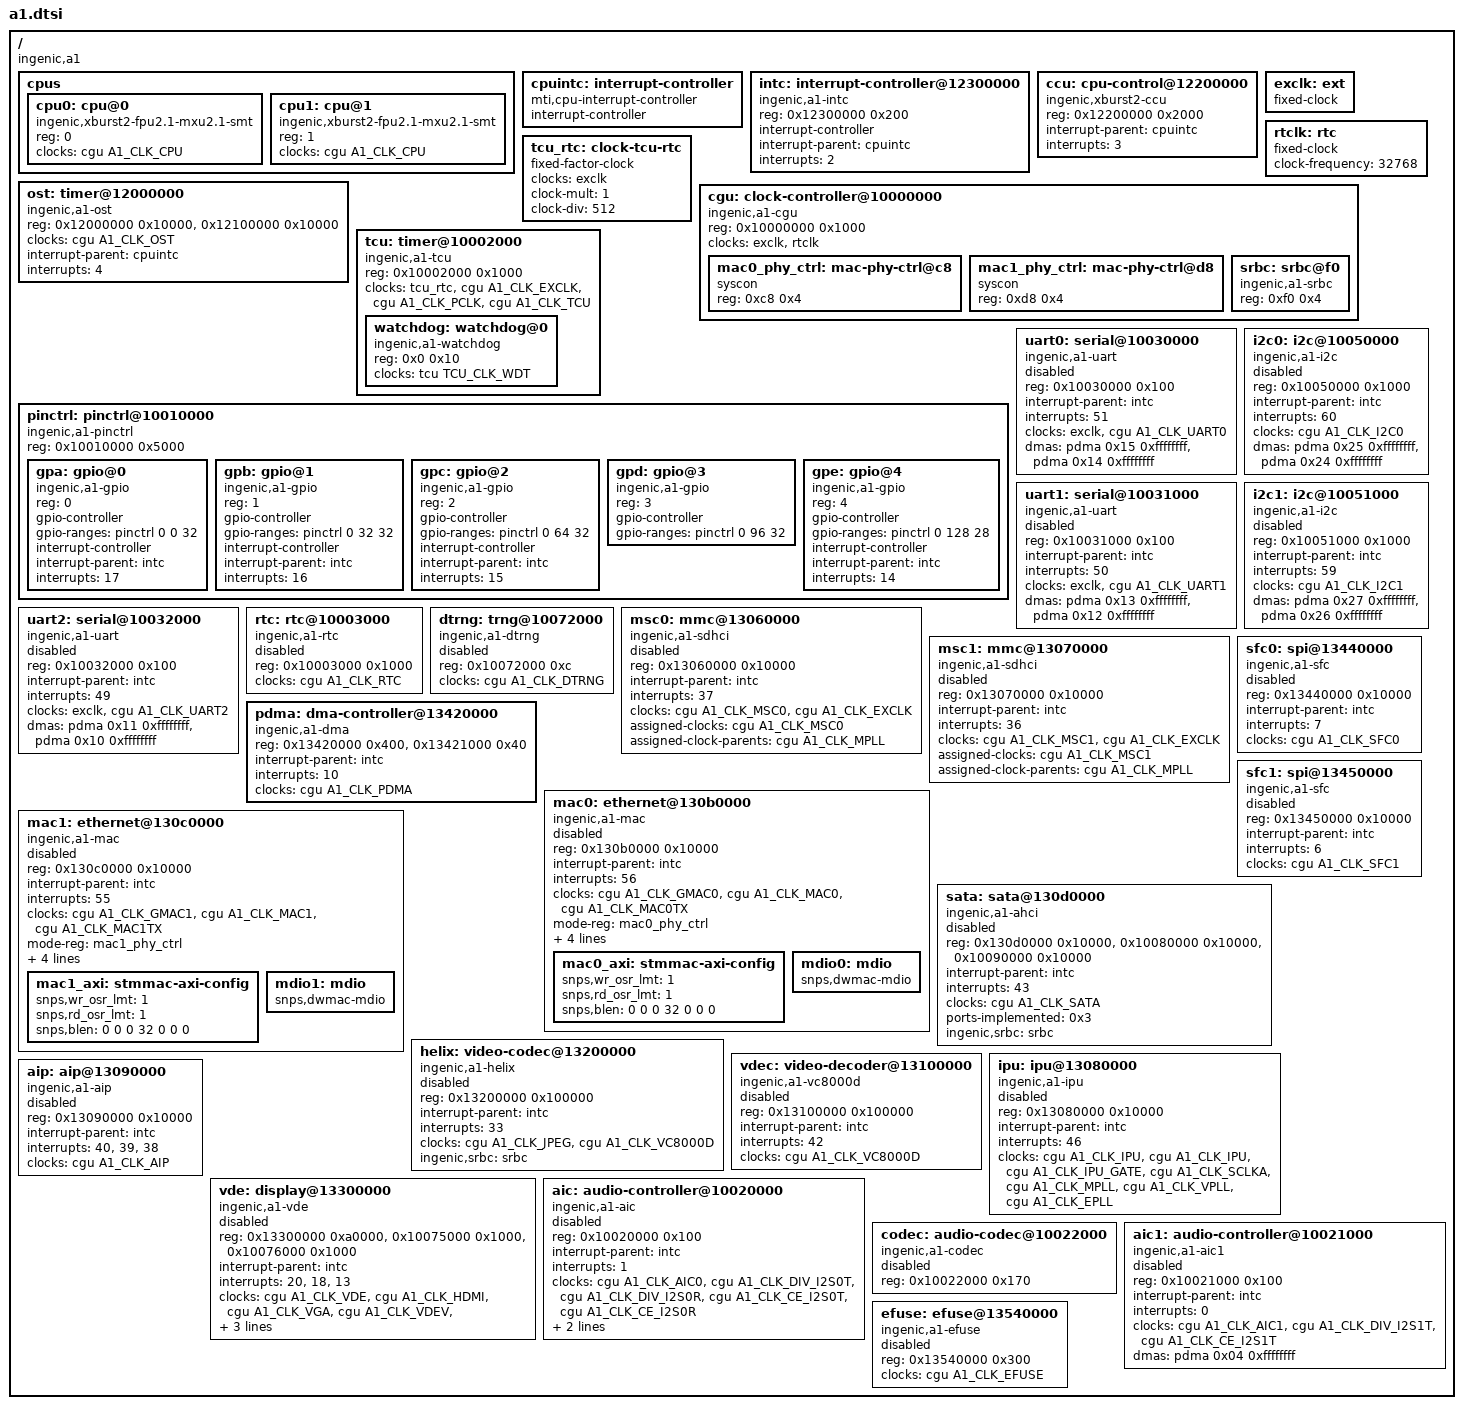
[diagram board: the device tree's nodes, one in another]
// SPDX-License-Identifier: GPL-2.0
#include <dt-bindings/clock/ingenic,a1-cgu.h>
#include <dt-bindings/clock/ingenic,tcu.h>

/ {
	#address-cells = <1>;
	#size-cells = <1>;
	compatible = "ingenic,a1";

	cpus {
		#address-cells = <1>;
		#size-cells = <0>;

		cpu0: cpu@0 {
			device_type = "cpu";
			compatible = "ingenic,xburst2-fpu2.1-mxu2.1-smt";
			reg = <0>;

			clocks = <&cgu A1_CLK_CPU>;
		};

		cpu1: cpu@1 {
			device_type = "cpu";
			compatible = "ingenic,xburst2-fpu2.1-mxu2.1-smt";
			reg = <1>;

			clocks = <&cgu A1_CLK_CPU>;
		};
	};

	cpuintc: interrupt-controller {
		#address-cells = <0>;
		#interrupt-cells = <1>;
		interrupt-controller;
		compatible = "mti,cpu-interrupt-controller";
	};

	/* One 0x100 window per core */
	intc: interrupt-controller@12300000 {
		compatible = "ingenic,a1-intc", "ingenic,t41-intc";
		reg = <0x12300000 0x200>;

		interrupt-controller;
		#interrupt-cells = <1>;

		interrupt-parent = <&cpuintc>;
		interrupts = <2>;
	};

	ccu: cpu-control@12200000 {
		compatible = "ingenic,xburst2-ccu";
		reg = <0x12200000 0x2000>;

		interrupt-parent = <&cpuintc>;
		interrupts = <3>;
	};

	exclk: ext {
		compatible = "fixed-clock";
		#clock-cells = <0>;
	};

	rtclk: rtc {
		compatible = "fixed-clock";
		#clock-cells = <0>;
		clock-frequency = <32768>;
	};

	/* RTC_EN of the TCU clocks EXCLK / 512, not the 32 kHz */
	tcu_rtc: clock-tcu-rtc {
		compatible = "fixed-factor-clock";
		clocks = <&exclk>;
		clock-mult = <1>;
		clock-div = <512>;
		#clock-cells = <0>;
	};

	cgu: clock-controller@10000000 {
		compatible = "ingenic,a1-cgu", "simple-mfd";
		reg = <0x10000000 0x1000>;
		#address-cells = <1>;
		#size-cells = <1>;
		ranges = <0x0 0x10000000 0x1000>;

		#clock-cells = <1>;

		clocks = <&exclk>, <&rtclk>;
		clock-names = "ext", "rtc";

		mac0_phy_ctrl: mac-phy-ctrl@c8 {
			compatible = "syscon";
			reg = <0xc8 0x4>;
		};

		mac1_phy_ctrl: mac-phy-ctrl@d8 {
			compatible = "syscon";
			reg = <0xd8 0x4>;
		};

		srbc: srbc@f0 {
			compatible = "ingenic,a1-srbc", "syscon";
			reg = <0xf0 0x4>;
		};
	};

	ost: timer@12000000 {
		compatible = "ingenic,a1-ost", "ingenic,t41-ost";
		reg = <0x12000000 0x10000>, <0x12100000 0x10000>;
		reg-names = "global", "core";

		clocks = <&cgu A1_CLK_OST>;
		clock-names = "ost";

		interrupt-parent = <&cpuintc>;
		interrupts = <4>;
	};

	tcu: timer@10002000 {
		compatible = "ingenic,a1-tcu", "ingenic,t32-tcu", "simple-mfd";
		reg = <0x10002000 0x1000>;
		#address-cells = <1>;
		#size-cells = <1>;
		ranges = <0x0 0x10002000 0x1000>;

		#clock-cells = <1>;

		clocks = <&tcu_rtc>,
			 <&cgu A1_CLK_EXCLK>,
			 <&cgu A1_CLK_PCLK>,
			 <&cgu A1_CLK_TCU>;
		clock-names = "rtc", "ext", "pclk", "tcu";

		watchdog: watchdog@0 {
			compatible = "ingenic,a1-watchdog", "ingenic,jz4780-watchdog";
			reg = <0x0 0x10>;

			clocks = <&tcu TCU_CLK_WDT>;
			clock-names = "wdt";
		};
	};

	pinctrl: pinctrl@10010000 {
		compatible = "ingenic,a1-pinctrl";
		reg = <0x10010000 0x5000>;

		#address-cells = <1>;
		#size-cells = <0>;

		gpa: gpio@0 {
			compatible = "ingenic,a1-gpio";
			reg = <0>;

			gpio-controller;
			gpio-ranges = <&pinctrl 0 0 32>;
			#gpio-cells = <2>;

			interrupt-controller;
			#interrupt-cells = <2>;

			interrupt-parent = <&intc>;
			interrupts = <17>;
		};

		gpb: gpio@1 {
			compatible = "ingenic,a1-gpio";
			reg = <1>;

			gpio-controller;
			gpio-ranges = <&pinctrl 0 32 32>;
			#gpio-cells = <2>;

			interrupt-controller;
			#interrupt-cells = <2>;

			interrupt-parent = <&intc>;
			interrupts = <16>;
		};

		gpc: gpio@2 {
			compatible = "ingenic,a1-gpio";
			reg = <2>;

			gpio-controller;
			gpio-ranges = <&pinctrl 0 64 32>;
			#gpio-cells = <2>;

			interrupt-controller;
			#interrupt-cells = <2>;

			interrupt-parent = <&intc>;
			interrupts = <15>;
		};

		/* No interrupt line */
		gpd: gpio@3 {
			compatible = "ingenic,a1-gpio";
			reg = <3>;

			gpio-controller;
			gpio-ranges = <&pinctrl 0 96 32>;
			#gpio-cells = <2>;
		};

		gpe: gpio@4 {
			compatible = "ingenic,a1-gpio";
			reg = <4>;

			gpio-controller;
			gpio-ranges = <&pinctrl 0 128 28>;
			#gpio-cells = <2>;

			interrupt-controller;
			#interrupt-cells = <2>;

			interrupt-parent = <&intc>;
			interrupts = <14>;
		};
	};

	uart0: serial@10030000 {
		compatible = "ingenic,a1-uart", "ingenic,x1000-uart";
		reg = <0x10030000 0x100>;

		interrupt-parent = <&intc>;
		interrupts = <51>;

		clocks = <&exclk>, <&cgu A1_CLK_UART0>;
		clock-names = "baud", "module";

		dmas = <&pdma 0x15 0xffffffff>, <&pdma 0x14 0xffffffff>;
		dma-names = "rx", "tx";

		status = "disabled";
	};

	uart1: serial@10031000 {
		compatible = "ingenic,a1-uart", "ingenic,x1000-uart";
		reg = <0x10031000 0x100>;

		interrupt-parent = <&intc>;
		interrupts = <50>;

		clocks = <&exclk>, <&cgu A1_CLK_UART1>;
		clock-names = "baud", "module";

		dmas = <&pdma 0x13 0xffffffff>, <&pdma 0x12 0xffffffff>;
		dma-names = "rx", "tx";

		status = "disabled";
	};

	uart2: serial@10032000 {
		compatible = "ingenic,a1-uart", "ingenic,x1000-uart";
		reg = <0x10032000 0x100>;

		interrupt-parent = <&intc>;
		interrupts = <49>;

		clocks = <&exclk>, <&cgu A1_CLK_UART2>;
		clock-names = "baud", "module";

		dmas = <&pdma 0x11 0xffffffff>, <&pdma 0x10 0xffffffff>;
		dma-names = "rx", "tx";

		status = "disabled";
	};

	i2c0: i2c@10050000 {
		compatible = "ingenic,a1-i2c", "ingenic,x1000-i2c";
		reg = <0x10050000 0x1000>;

		interrupt-parent = <&intc>;
		interrupts = <60>;

		clocks = <&cgu A1_CLK_I2C0>;

		dmas = <&pdma 0x25 0xffffffff>, <&pdma 0x24 0xffffffff>;
		dma-names = "rx", "tx";

		#address-cells = <1>;
		#size-cells = <0>;

		status = "disabled";
	};

	i2c1: i2c@10051000 {
		compatible = "ingenic,a1-i2c", "ingenic,x1000-i2c";
		reg = <0x10051000 0x1000>;

		interrupt-parent = <&intc>;
		interrupts = <59>;

		clocks = <&cgu A1_CLK_I2C1>;

		dmas = <&pdma 0x27 0xffffffff>, <&pdma 0x26 0xffffffff>;
		dma-names = "rx", "tx";

		#address-cells = <1>;
		#size-cells = <0>;

		status = "disabled";
	};

	rtc: rtc@10003000 {
		compatible = "ingenic,a1-rtc";
		reg = <0x10003000 0x1000>;

		clocks = <&cgu A1_CLK_RTC>;

		status = "disabled";
	};

	dtrng: trng@10072000 {
		compatible = "ingenic,a1-dtrng", "ingenic,x1830-dtrng";
		reg = <0x10072000 0xc>;

		clocks = <&cgu A1_CLK_DTRNG>;

		status = "disabled";
	};

	msc0: mmc@13060000 {
		compatible = "ingenic,a1-sdhci", "ingenic,t32-sdhci";
		reg = <0x13060000 0x10000>;

		interrupt-parent = <&intc>;
		interrupts = <37>;

		clocks = <&cgu A1_CLK_MSC0>, <&cgu A1_CLK_EXCLK>;
		clock-names = "mmc", "ext";

		/* the MSC mux may be left on a source the CGU does not list */
		assigned-clocks = <&cgu A1_CLK_MSC0>;
		assigned-clock-parents = <&cgu A1_CLK_MPLL>;

		status = "disabled";
	};

	msc1: mmc@13070000 {
		compatible = "ingenic,a1-sdhci", "ingenic,t32-sdhci";
		reg = <0x13070000 0x10000>;

		interrupt-parent = <&intc>;
		interrupts = <36>;

		clocks = <&cgu A1_CLK_MSC1>, <&cgu A1_CLK_EXCLK>;
		clock-names = "mmc", "ext";

		/* the MSC mux may be left on a source the CGU does not list */
		assigned-clocks = <&cgu A1_CLK_MSC1>;
		assigned-clock-parents = <&cgu A1_CLK_MPLL>;

		status = "disabled";
	};

	pdma: dma-controller@13420000 {
		compatible = "ingenic,a1-dma", "ingenic,x1830-dma";
		reg = <0x13420000 0x400>, <0x13421000 0x40>;

		interrupt-parent = <&intc>;
		interrupts = <10>;

		clocks = <&cgu A1_CLK_PDMA>;

		#dma-cells = <2>;
	};

	sfc0: spi@13440000 {
		compatible = "ingenic,a1-sfc", "ingenic,t32-sfc";
		reg = <0x13440000 0x10000>;

		interrupt-parent = <&intc>;
		interrupts = <7>;

		clocks = <&cgu A1_CLK_SFC0>;
		clock-names = "sfc";

		#address-cells = <1>;
		#size-cells = <0>;

		status = "disabled";
	};

	sfc1: spi@13450000 {
		compatible = "ingenic,a1-sfc", "ingenic,t32-sfc";
		reg = <0x13450000 0x10000>;

		interrupt-parent = <&intc>;
		interrupts = <6>;

		clocks = <&cgu A1_CLK_SFC1>;
		clock-names = "sfc";

		#address-cells = <1>;
		#size-cells = <0>;

		status = "disabled";
	};

	mac0: ethernet@130b0000 {
		compatible = "ingenic,a1-mac", "snps,dwxgmac-2.10", "snps,dwxgmac";
		reg = <0x130b0000 0x10000>;

		interrupt-parent = <&intc>;
		interrupts = <56>;
		interrupt-names = "macirq";

		clocks = <&cgu A1_CLK_GMAC0>, <&cgu A1_CLK_MAC0>,
			 <&cgu A1_CLK_MAC0TX>;
		clock-names = "stmmaceth", "phy", "tx";

		mode-reg = <&mac0_phy_ctrl>;

		snps,axi-config = <&mac0_axi>;
		snps,txpbl = <32>;
		snps,rxpbl = <32>;
		snps,force_sf_dma_mode;

		status = "disabled";

		mac0_axi: stmmac-axi-config {
			snps,wr_osr_lmt = <1>;
			snps,rd_osr_lmt = <1>;
			snps,blen = <0 0 0 32 0 0 0>;
		};

		mdio0: mdio {
			compatible = "snps,dwmac-mdio";
			#address-cells = <1>;
			#size-cells = <0>;
		};
	};

	mac1: ethernet@130c0000 {
		compatible = "ingenic,a1-mac", "snps,dwxgmac-2.10", "snps,dwxgmac";
		reg = <0x130c0000 0x10000>;

		interrupt-parent = <&intc>;
		interrupts = <55>;
		interrupt-names = "macirq";

		clocks = <&cgu A1_CLK_GMAC1>, <&cgu A1_CLK_MAC1>,
			 <&cgu A1_CLK_MAC1TX>;
		clock-names = "stmmaceth", "phy", "tx";

		mode-reg = <&mac1_phy_ctrl>;

		snps,axi-config = <&mac1_axi>;
		snps,txpbl = <32>;
		snps,rxpbl = <32>;
		snps,force_sf_dma_mode;

		status = "disabled";

		mac1_axi: stmmac-axi-config {
			snps,wr_osr_lmt = <1>;
			snps,rd_osr_lmt = <1>;
			snps,blen = <0 0 0 32 0 0 0>;
		};

		mdio1: mdio {
			compatible = "snps,dwmac-mdio";
			#address-cells = <1>;
			#size-cells = <0>;
		};
	};

	sata: sata@130d0000 {
		compatible = "ingenic,a1-ahci";
		reg = <0x130d0000 0x10000>, <0x10080000 0x10000>,
		      <0x10090000 0x10000>;
		reg-names = "ahci", "phy0", "phy1";

		interrupt-parent = <&intc>;
		interrupts = <43>;

		clocks = <&cgu A1_CLK_SATA>;

		ports-implemented = <0x3>;
		ingenic,srbc = <&srbc>;

		status = "disabled";
	};

	helix: video-codec@13200000 {
		compatible = "ingenic,a1-helix";
		reg = <0x13200000 0x100000>;

		interrupt-parent = <&intc>;
		interrupts = <33>;

		clocks = <&cgu A1_CLK_JPEG>, <&cgu A1_CLK_VC8000D>;
		clock-names = "gate_jpeg", "gate_vc8000d";

		ingenic,srbc = <&srbc>;

		status = "disabled";
	};

	vdec: video-decoder@13100000 {
		compatible = "ingenic,a1-vc8000d";
		reg = <0x13100000 0x100000>;

		interrupt-parent = <&intc>;
		interrupts = <42>;

		clocks = <&cgu A1_CLK_VC8000D>;
		clock-names = "gate_vc8000d";

		status = "disabled";
	};

	ipu: ipu@13080000 {
		compatible = "ingenic,a1-ipu";
		reg = <0x13080000 0x10000>;

		interrupt-parent = <&intc>;
		interrupts = <46>;

		/* the vendor stack names the mux and the divider apart; here they are one clock */
		clocks = <&cgu A1_CLK_IPU>, <&cgu A1_CLK_IPU>,
			 <&cgu A1_CLK_IPU_GATE>, <&cgu A1_CLK_SCLKA>,
			 <&cgu A1_CLK_MPLL>, <&cgu A1_CLK_VPLL>,
			 <&cgu A1_CLK_EPLL>;
		clock-names = "mux_ipu", "div_ipu", "gate_ipu", "sclka",
			      "mpll", "vpll", "epll";

		status = "disabled";
	};

	aip: aip@13090000 {
		compatible = "ingenic,a1-aip";
		reg = <0x13090000 0x10000>;

		interrupt-parent = <&intc>;
		interrupts = <40>, <39>, <38>;

		clocks = <&cgu A1_CLK_AIP>;
		clock-names = "gate_aip";

		status = "disabled";
	};

	vde: display@13300000 {
		compatible = "ingenic,a1-vde";
		reg = <0x13300000 0xa0000>, <0x10075000 0x1000>,
		      <0x10076000 0x1000>;

		interrupt-parent = <&intc>;
		interrupts = <20>, <18>, <13>;

		/* the vendor stack names each mux and divider apart; here they are one clock */
		clocks = <&cgu A1_CLK_VDE>, <&cgu A1_CLK_HDMI>,
			 <&cgu A1_CLK_VGA>, <&cgu A1_CLK_VDEV>,
			 <&cgu A1_CLK_VDEA>, <&cgu A1_CLK_VDEM>,
			 <&cgu A1_CLK_VDEV>, <&cgu A1_CLK_VDEA>,
			 <&cgu A1_CLK_VDEM>;
		clock-names = "gate_vde", "gate_hdmi", "gate_vga",
			      "div_vdev", "div_vdea", "div_vdem",
			      "mux_vdev", "mux_vdea", "mux_vdem";

		status = "disabled";
	};

	aic: audio-controller@10020000 {
		compatible = "ingenic,a1-aic";
		reg = <0x10020000 0x100>;

		interrupt-parent = <&intc>;
		interrupts = <1>;

		clocks = <&cgu A1_CLK_AIC0>,
			 <&cgu A1_CLK_DIV_I2S0T>,
			 <&cgu A1_CLK_DIV_I2S0R>,
			 <&cgu A1_CLK_CE_I2S0T>,
			 <&cgu A1_CLK_CE_I2S0R>;
		clock-names = "gate_aic", "div_i2st", "div_i2sr",
			      "ce_i2st", "ce_i2sr";

		dmas = <&pdma 0x07 0xffffffff>,
		       <&pdma 0x06 0xffffffff>,
		       <&pdma 0x05 0xffffffff>;
		dma-names = "rx", "tx", "aec";

		status = "disabled";
	};

	codec: audio-codec@10022000 {
		compatible = "ingenic,a1-codec";
		reg = <0x10022000 0x170>;

		status = "disabled";
	};

	aic1: audio-controller@10021000 {
		compatible = "ingenic,a1-aic1";
		reg = <0x10021000 0x100>;

		interrupt-parent = <&intc>;
		interrupts = <0>;

		clocks = <&cgu A1_CLK_AIC1>,
			 <&cgu A1_CLK_DIV_I2S1T>,
			 <&cgu A1_CLK_CE_I2S1T>;
		clock-names = "gate_aic", "div_i2st", "ce_i2st";

		dmas = <&pdma 0x04 0xffffffff>;
		dma-names = "tx";

		status = "disabled";
	};

	efuse: efuse@13540000 {
		compatible = "ingenic,a1-efuse";
		reg = <0x13540000 0x300>;

		clocks = <&cgu A1_CLK_EFUSE>;

		status = "disabled";
	};
};
